# W806 register map
Vendor: Beijing Lianshengde Micro-electronics Co., Ltd.; File version: 1.0
W806 general purpose microcontroller
Registers are 32-bit, read-write, no defined reset value unless marked. A register's access mark holds for its fields unless they carry their own. Offsets are from the block's base; lines under a group give offsets from that group; [hi:lo] are bit positions; {n}, {i} and the like mark numbered series; 'fields as' and 'values as' point back to an identical list; <NAME> marks a mode.

## Memory map
0x40000000 RSA — RSA Montgomery FIOS algorithm coprocessor
0x40000800 DMA — Direct memory access module
0x40000D00 PMU — Power management unit
0x40000E00 RCC — System clock and reset controller
0x40002000 FLASH — Internal flash controller
0x40010000 I2C — Inter-Integrated Circuit bus
0x40010200 ADC — Analog-digital converter
0x40010400 SPI — Serial peripheral interface
{0x40010600+0x200*n} UART{n} (n=0..5) — Universal Asynchronous Receiver/Transmitter
0x40011200 GPIO[{x}] (x=A,B; step 0x200) — General purpose input/output module
0x40011600 WDOG — Watchdog module
0x40011800 TIMER
0x40011E00 PWM — Pulse-width modulation module
0x40012400 TOUCH — Touchpad sensor module

## DMA — Direct memory access module
Base 0x40000800
Same registers: RSA 0x40000000, FLASH 0x40002000, I2C 0x40010000, ADC 0x40010200, WDOG 0x40011600, PWM 0x40011E00, TOUCH 0x40012400
0x00 todo — ??

## PMU — Power management unit
Base 0x40000D00
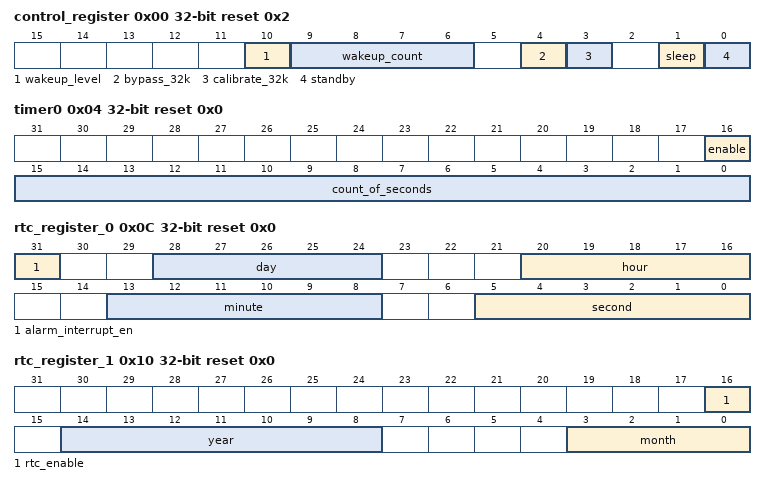
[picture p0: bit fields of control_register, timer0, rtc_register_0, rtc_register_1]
0x00 control_register reset 0x2 (reset mask 0x45B) — PMU control register
  [10] wakeup_level — IO wake-up polarity selection
    0=low (Low level interrupts); 1=High level interrupt
  [9:6] wakeup_count — IO wake-up Minimum hold count of 128ms
  [4] bypass_32k — Bypass 32k oscillator
    0=Disable bypass 32k oscillator; 1=Enable bypass 32k oscillator
  [3] calibrate_32k — Calibrate 32k oscillator
    0=off (Stop calibrate 32k oscillator); 1=on (Start up calibrate 32k oscillator)
  [1] sleep — Sleep enable
    0=Disable sleep; 1=Enable sleep
  [0] standby — Standby enable
    0=Disable standby; 1=Enable standby
0x04 timer0 reset 0x0
  [16] enable — PMU timer0 enable
    0=Disable timer0; 1=Enable timer0
  [15:0] count_of_seconds — PMU timer0 initial count of seconds register
0x0C rtc_register_0 reset 0x0
  [31] alarm_interrupt_en — Alarm interrupt enable
    0=disable (RTC does not generate Alarm Interrupts); 1=enable (RTC triggers the Alarm Interrupt)
  [28:24] day
  [20:16] hour
  [13:8] minute
  [5:0] second
0x10 rtc_register_1 reset 0x0
  [16] rtc_enable
    0=disable (RTC disable); 1=enable (RTC enable)
  [14:8] year
  [3:0] month
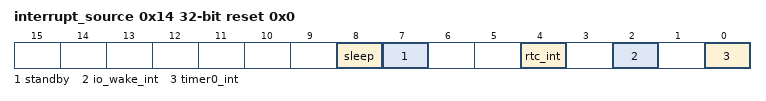
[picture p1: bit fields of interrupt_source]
0x14 interrupt_source reset 0x0 — PMU interrupt source register
  [8] sleep — Whether power-on from sleep
    0=disappear wake up from sleep; 1=appear wake up from sleep, set clear
  [7] standby — Whether power-on from standby
    0=disappear wake up from standby; 1=appear wake up from standby, set clear
  [4] rtc_int — RTC interrupt flag
    0=no_interrupt (No RTC interrupt is generated.); 1=has_interrupt_set_clr (RTC interrupt is generated, set clear)
  [2] io_wake_int — IO wake up interrupt flag
    0=no_interrupt (No IO wake up interrupt is generated.); 1=has_interrupt_set_clr (IO wake up interrupt is generated, set clear)
  [0] timer0_int — PMU TIMER0 interrupt flag
    0=no_interrupt (No PMU TIMER0 interrupt is generated.); 1=has_interrupt_set_clr (PMU TIMER0 interrupt is generated, set clear)

## SPI — Serial peripheral interface
Base 0x40010400
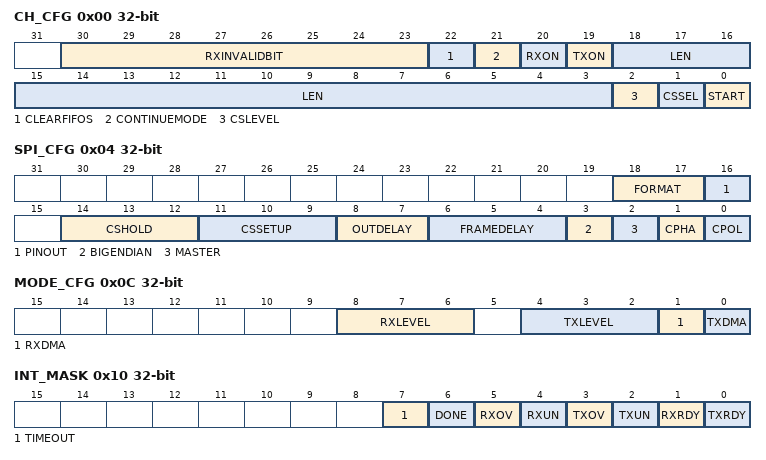
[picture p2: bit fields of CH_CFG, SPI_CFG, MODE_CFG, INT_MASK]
0x00 CH_CFG — Channel configuration register
  [30:23] RXINVALIDBIT
  [22] CLEARFIFOS
  [21] CONTINUEMODE
  [20] RXON
  [19] TXON
  [18:3] LEN — Transfer length
  [2] CSLEVEL — Chip select level
  [1] CSSEL — Chip select
  [0] START — Start transfer
0x04 SPI_CFG — SPI configuration register
  [18:17] FORMAT — SPI format
  [16] PINOUT
  [14:12] CSHOLD — Chip select hold
  [11:9] CSSETUP — Chip select setup
  [8:7] OUTDELAY — Output delay
  [6:4] FRAMEDELAY
  [3] BIGENDIAN
  [2] MASTER — Master mode
  [1] CPHA — Clock phase
  [0] CPOL — Clock polarity
0x08 CLK_CFG — Clock configuration register
  [15:0] DIV — Clock divider
0x0C MODE_CFG — Mode configuration register
  [8:6] RXLEVEL — RX FIFO level
  [4:2] TXLEVEL — TX FIFO level
  [1] RXDMA — RX DMA enable
  [0] TXDMA — TX DMA enable
0x10 INT_MASK — Interrupt mask register
  [7] TIMEOUT — Timeout interrupt mask
  [6] DONE — Transfer done interrupt mask
  [5] RXOV — RX overrun interrupt mask
  [4] RXUN — RX underrun interrupt mask
  [3] TXOV — TX overrun interrupt mask
  [2] TXUN — TX underrun interrupt mask
  [1] RXRDY — RX ready interrupt mask
  [0] TXRDY — TX ready interrupt mask
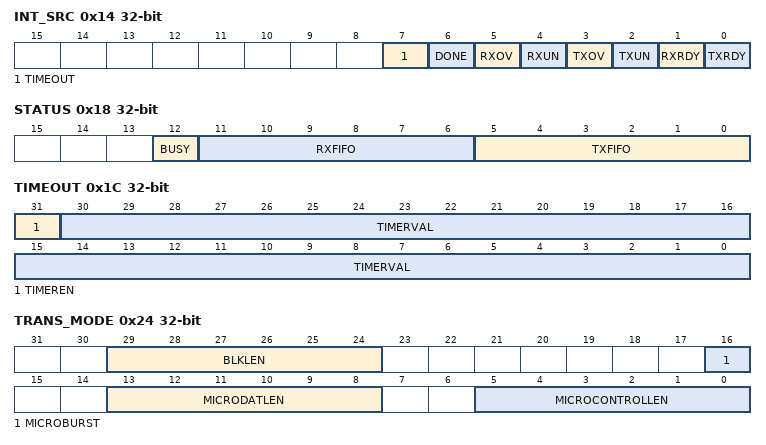
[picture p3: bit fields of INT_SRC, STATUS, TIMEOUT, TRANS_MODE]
0x14 INT_SRC — Interrupt source register
  [7] TIMEOUT — Timeout interrupt
  [6] DONE — Transfer done interrupt
  [5] RXOV — RX overrun interrupt
  [4] RXUN — RX underrun interrupt
  [3] TXOV — TX overrun interrupt
  [2] TXUN — TX underrun interrupt
  [1] RXRDY — RX ready interrupt
  [0] TXRDY — TX ready interrupt
0x18 STATUS ro
  [12] BUSY — SPI busy flag
  [11:6] RXFIFO — RX FIFO level
  [5:0] TXFIFO — TX FIFO level
0x1C TIMEOUT
  [31] TIMEREN — Timeout enable
  [30:0] TIMERVAL — Timeout value
0x20 TXDATA wo
0x24 TRANS_MODE — Transfer mode register
  [29:24] BLKLEN — Block length
  [16] MICROBURST — Microburst mode
  [13:8] MICRODATLEN — Microburst data length
  [5:0] MICROCONTROLLEN — Microburst control length
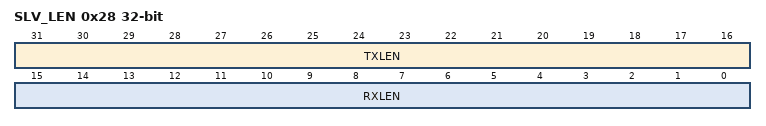
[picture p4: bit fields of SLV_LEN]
0x28 SLV_LEN ro — Slave transfer length register
  [31:16] TXLEN — TX length
  [15:0] RXLEN — RX length
0x2C RSV ro — Reserved
0x30 RXDATA ro

## Licence text in the file
Copyright (c) 2021 Rustcc Embedded Wechat Group W806-SVD is licensed under Mulan PSL v2. You can use this software according to the terms and conditions of the Mulan PSL v2. You may obtain a copy of Mulan PSL v2 at: http://license.coscl.org.cn/MulanPSL2 THIS SOFTWARE IS PROVIDED ON AN "AS IS" BASIS, WITHOUT WARRANTIES OF ANY KIND, EITHER EXPRESS OR IMPLIED, INCLUDING BUT NOT LIMITED TO NON-INFRINGEMENT, MERCHANTABILITY OR FIT FOR A PARTICULAR PURPOSE. See the Mulan PSL v2 for more details.
